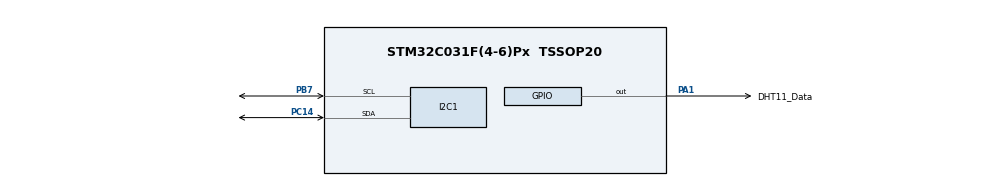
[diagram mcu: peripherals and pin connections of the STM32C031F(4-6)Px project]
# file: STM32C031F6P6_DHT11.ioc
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I2C1.OwnAddress=I2C_SLAVE_ADDRESS
I2C1.Timing=0x40000A0B
Mcu.Family=STM32C0
Mcu.Name=STM32C031F(4-6)Px
Mcu.Package=TSSOP20
NVIC.I2C1_IRQn=true\:0\:0\:false\:false\:true\:true\:true\:true
PA1.GPIO_Label=DHT11_Data
PA1.Signal=GPIO_Output
PA13.Mode=Serial_Wire
PA13.Signal=DEBUG_SWDIO
PA14-BOOT0.Mode=Serial_Wire
PA14-BOOT0.Signal=DEBUG_SWCLK
PB7.Mode=I2C
PB7.Signal=I2C1_SCL
PC14-OSCX_IN\ (PC14).Mode=I2C
PC14-OSCX_IN\ (PC14).Signal=I2C1_SDA
ProjectManager.HeapSize=0x200
ProjectManager.StackSize=0x400
ProjectManager.TargetToolchain=STM32CubeIDE
RCC.ADCFreq_Value=12000000
RCC.AHBFreq_Value=12000000
RCC.CortexFreq_Value=12000000
RCC.EXTERNAL_CLOCK_VALUE=12288000
RCC.HCLKFreq_Value=12000000
RCC.HSE_VALUE=8000000
RCC.HSI_VALUE=48000000
RCC.LSE_VALUE=32768
RCC.SYSCLKFreq_VALUE=12000000
TIM1.Period=TIM1_ARR
TIM1.Prescaler=TIM1_PRESCALER
VP_TIM1_VS_ClockSourceINT.Mode=Internal
board=custom

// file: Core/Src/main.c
/* USER CODE BEGIN Header */
/**
  ******************************************************************************
  * @file           : main.c
  * @brief          : Main program body
  ******************************************************************************
  * @attention
  *
  * Copyright (c) 2024 STMicroelectronics.
  * All rights reserved.
  *
  * This software is licensed under terms that can be found in the LICENSE file
  * in the root directory of this software component.
  * If no LICENSE file comes with this software, it is provided AS-IS.
  *
  ******************************************************************************
  */
/* USER CODE END Header */
#include "main.h"

/* USER CODE BEGIN Includes */
#include "DHT11.h"
#include "module_register.h"
/* USER CODE END Includes */

I2C_HandleTypeDef hi2c1;

TIM_HandleTypeDef htim1;

/* USER CODE BEGIN PV */
DHT11_data data;
uint32_t counter_glob = 0;
uint8_t I2c_slave_address = 25;

volatile float real_value = 0;
volatile float read_value = 0;
volatile uint64_t stored_value = 0;
/* USER CODE END PV */

void SystemClock_Config(void);
static void MX_GPIO_Init(void);
static void MX_TIM1_Init(void);
static void MX_I2C1_Init(void);
/* USER CODE BEGIN PFP */
static void real_I2C1_Init(void);
/* USER CODE END PFP */

int main(void)
{

  /* USER CODE BEGIN 1 */
  data.GPIO_Pin = DHT11_Data_Pin;
  data.GPIO_Port = DHT11_Data_GPIO_Port;
  /* USER CODE END 1 */

  /* MCU Configuration--------------------------------------------------------*/

  /* Reset of all peripherals, Initializes the Flash interface and the Systick. */
  HAL_Init();

  /* Configure the system clock */
  SystemClock_Config();

  /* Initialize all configured peripherals */
  MX_GPIO_Init();
  MX_TIM1_Init();
  MX_I2C1_Init();
  /* USER CODE BEGIN 2 */

  I2c_slave_address = 12;
  real_I2C1_Init();

  if (HAL_TIM_Base_Start(&htim1) != HAL_OK)      Error_Handler();
  if (HAL_I2C_EnableListen_IT(&hi2c1) != HAL_OK) Error_Handler();

  /* USER CODE END 2 */

  /* Infinite loop */
  /* USER CODE BEGIN WHILE */
  while (1)
  {
	counter_glob++;
	DHT_GetData(&data);

	set_sensor_value_1(data.humidity);
	set_sensor_value_2(data.temperature);
	real_value = data.humidity;
	read_value = get_sensor_value_1();

	HAL_Delay(1000);

    /* USER CODE END WHILE */

  }
}

void SystemClock_Config(void)
{
  RCC_OscInitTypeDef RCC_OscInitStruct = {0};
  RCC_ClkInitTypeDef RCC_ClkInitStruct = {0};

  /** Initializes the RCC Oscillators according to the specified parameters
  * in the RCC_OscInitTypeDef structure.
  */
  RCC_OscInitStruct.OscillatorType = RCC_OSCILLATORTYPE_HSI;
  RCC_OscInitStruct.HSIState = RCC_HSI_ON;
  RCC_OscInitStruct.HSIDiv = RCC_HSI_DIV4;
  RCC_OscInitStruct.HSICalibrationValue = RCC_HSICALIBRATION_DEFAULT;
  if (HAL_RCC_OscConfig(&RCC_OscInitStruct) != HAL_OK)
  {
    Error_Handler();
  }

  /** Initializes the CPU, AHB and APB buses clocks
  */
  RCC_ClkInitStruct.ClockType = RCC_CLOCKTYPE_HCLK|RCC_CLOCKTYPE_SYSCLK
                              |RCC_CLOCKTYPE_PCLK1;
  RCC_ClkInitStruct.SYSCLKSource = RCC_SYSCLKSOURCE_HSI;
  RCC_ClkInitStruct.SYSCLKDivider = RCC_SYSCLK_DIV1;
  RCC_ClkInitStruct.AHBCLKDivider = RCC_HCLK_DIV1;
  RCC_ClkInitStruct.APB1CLKDivider = RCC_APB1_DIV1;

  if (HAL_RCC_ClockConfig(&RCC_ClkInitStruct, FLASH_LATENCY_0) != HAL_OK)
  {
    Error_Handler();
  }
}

static void MX_I2C1_Init(void)
{

  /* USER CODE BEGIN I2C1_Init 1 */
  #ifdef USE_CUBEMX_SHITTY_CODE// Prevent CubeMX shitty code
  /* USER CODE END I2C1_Init 1 */
  hi2c1.Instance = I2C1;
  hi2c1.Init.Timing = 0x40000A0B;
  hi2c1.Init.OwnAddress1 = I2C_SLAVE_ADDRESS;
  hi2c1.Init.AddressingMode = I2C_ADDRESSINGMODE_7BIT;
  hi2c1.Init.DualAddressMode = I2C_DUALADDRESS_DISABLE;
  hi2c1.Init.OwnAddress2 = 0;
  hi2c1.Init.OwnAddress2Masks = I2C_OA2_NOMASK;
  hi2c1.Init.GeneralCallMode = I2C_GENERALCALL_DISABLE;
  hi2c1.Init.NoStretchMode = I2C_NOSTRETCH_DISABLE;
  if (HAL_I2C_Init(&hi2c1) != HAL_OK)
  {
    Error_Handler();
  }

  /** Configure Analogue filter
  */
  if (HAL_I2CEx_ConfigAnalogFilter(&hi2c1, I2C_ANALOGFILTER_ENABLE) != HAL_OK)
  {
    Error_Handler();
  }

  /** Configure Digital filter
  */
  if (HAL_I2CEx_ConfigDigitalFilter(&hi2c1, 0) != HAL_OK)
  {
    Error_Handler();
  }
  /* USER CODE BEGIN I2C1_Init 2 */
  #endif
  /* USER CODE END I2C1_Init 2 */

}

static void MX_TIM1_Init(void)
{

  TIM_ClockConfigTypeDef sClockSourceConfig = {0};
  TIM_MasterConfigTypeDef sMasterConfig = {0};

  htim1.Instance = TIM1;
  htim1.Init.Prescaler = TIM1_PRESCALER;
  htim1.Init.CounterMode = TIM_COUNTERMODE_UP;
  htim1.Init.Period = TIM1_ARR;
  htim1.Init.ClockDivision = TIM_CLOCKDIVISION_DIV1;
  htim1.Init.RepetitionCounter = 0;
  htim1.Init.AutoReloadPreload = TIM_AUTORELOAD_PRELOAD_DISABLE;
  if (HAL_TIM_Base_Init(&htim1) != HAL_OK)
  {
    Error_Handler();
  }
  sClockSourceConfig.ClockSource = TIM_CLOCKSOURCE_INTERNAL;
  if (HAL_TIM_ConfigClockSource(&htim1, &sClockSourceConfig) != HAL_OK)
  {
    Error_Handler();
  }
  sMasterConfig.MasterOutputTrigger = TIM_TRGO_RESET;
  sMasterConfig.MasterOutputTrigger2 = TIM_TRGO2_RESET;
  sMasterConfig.MasterSlaveMode = TIM_MASTERSLAVEMODE_DISABLE;
  if (HAL_TIMEx_MasterConfigSynchronization(&htim1, &sMasterConfig) != HAL_OK)
  {
    Error_Handler();
  }

}

static void MX_GPIO_Init(void)
{
  GPIO_InitTypeDef GPIO_InitStruct = {0};

  /* GPIO Ports Clock Enable */
  __HAL_RCC_GPIOB_CLK_ENABLE();
  __HAL_RCC_GPIOC_CLK_ENABLE();
  __HAL_RCC_GPIOA_CLK_ENABLE();

  /*Configure GPIO pin Output Level */
  HAL_GPIO_WritePin(DHT11_Data_GPIO_Port, DHT11_Data_Pin, GPIO_PIN_RESET);

  /*Configure GPIO pin : DHT11_Data_Pin */
  GPIO_InitStruct.Pin = DHT11_Data_Pin;
  GPIO_InitStruct.Mode = GPIO_MODE_OUTPUT_PP;
  GPIO_InitStruct.Pull = GPIO_NOPULL;
  GPIO_InitStruct.Speed = GPIO_SPEED_FREQ_LOW;
  HAL_GPIO_Init(DHT11_Data_GPIO_Port, &GPIO_InitStruct);

}

/* USER CODE BEGIN 4 */

void microsecond_delay(uint16_t duration)
{
	__HAL_TIM_SET_COUNTER(&htim1, 0);                 // set the counter value a 0
	while (__HAL_TIM_GET_COUNTER(&htim1) < duration); // wait for the counter to reach the us input in the parameter
}

static void real_I2C1_Init(void)
{
	hi2c1.Instance = I2C1;
	hi2c1.Init.Timing = 0x40000A0B;
	hi2c1.Init.OwnAddress1 = (I2c_slave_address << 1);
	hi2c1.Init.AddressingMode = I2C_ADDRESSINGMODE_7BIT;
	hi2c1.Init.DualAddressMode = I2C_DUALADDRESS_DISABLE;
	hi2c1.Init.OwnAddress2 = 0;
	hi2c1.Init.OwnAddress2Masks = I2C_OA2_NOMASK;
	hi2c1.Init.GeneralCallMode = I2C_GENERALCALL_DISABLE;
	hi2c1.Init.NoStretchMode = I2C_NOSTRETCH_DISABLE;

	if (HAL_I2C_Init(&hi2c1) != HAL_OK)
	{
	Error_Handler();
	}

	/** Configure Analogue filter
	*/
	if (HAL_I2CEx_ConfigAnalogFilter(&hi2c1, I2C_ANALOGFILTER_ENABLE) != HAL_OK)
	{
	Error_Handler();
	}

	/** Configure Digital filter
	*/
	if (HAL_I2CEx_ConfigDigitalFilter(&hi2c1, 0) != HAL_OK)
	{
	Error_Handler();
	}
}

/* USER CODE END 4 */

void Error_Handler(void)
{
  __disable_irq();
  while (1)
  {
  }
}
